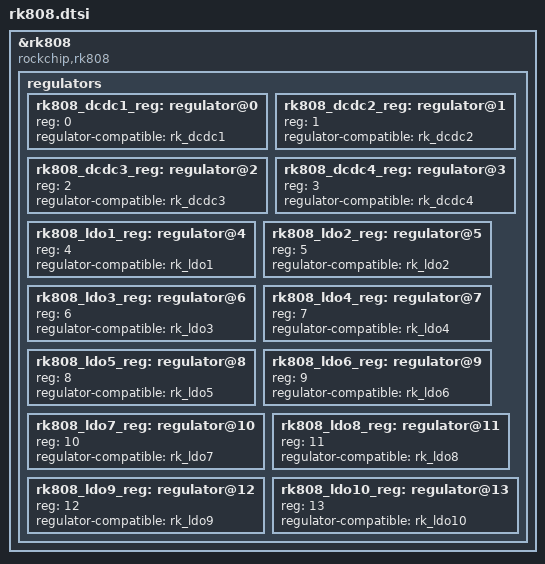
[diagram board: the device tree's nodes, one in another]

&rk808 {
	compatible = "rockchip,rk808";
	
	regulators {
		#address-cells = <1>;
		#size-cells = <0>;	

		rk808_dcdc1_reg: regulator@0 {
			reg = <0>;
			regulator-compatible = "rk_dcdc1";
		};

		rk808_dcdc2_reg: regulator@1 {
			reg = <1>;
			regulator-compatible = "rk_dcdc2";
		};

		rk808_dcdc3_reg: regulator@2 {
			reg = <2>;
			regulator-compatible = "rk_dcdc3";
		};

		rk808_dcdc4_reg: regulator@3 {
			reg = <3>;
			regulator-compatible = "rk_dcdc4";
		};

		rk808_ldo1_reg: regulator@4 {
			reg = <4>;
			regulator-compatible = "rk_ldo1";
		};

		rk808_ldo2_reg: regulator@5 {
			reg = <5>;
			regulator-compatible = "rk_ldo2";
		};

		rk808_ldo3_reg: regulator@6 {
			reg = <6>;
			regulator-compatible = "rk_ldo3";
		};

		rk808_ldo4_reg: regulator@7{
			reg = <7>;
			regulator-compatible = "rk_ldo4";
		};

		rk808_ldo5_reg: regulator@8{
			reg = <8>;
			regulator-compatible = "rk_ldo5";
		};

		rk808_ldo6_reg: regulator@9{
			reg = <9>;
			regulator-compatible = "rk_ldo6";
		};

		rk808_ldo7_reg: regulator@10 {
			reg = <10>;
			regulator-compatible = "rk_ldo7";
		};

		rk808_ldo8_reg: regulator@11{
			reg = <11>;
			regulator-compatible = "rk_ldo8";
		};
		
		rk808_ldo9_reg: regulator@12{
			reg = <12>;
			regulator-compatible = "rk_ldo9";
		};
		
		rk808_ldo10_reg: regulator@13{
			reg = <13>;
			regulator-compatible = "rk_ldo10";
		};

	};
};
